# Register Definitions: IP-XACT component
VLNV meklort:<PROJECT>:Register Definitions:1.0

## Address spaces and blocks
DEVICE.DEVICE: base 0xC0000000, range , width , register

## Registers
Registers are 32-bit, access not given, no defined reset value unless marked. A register's access mark holds for its fields unless they carry their own. Offsets are from the block's base; lines under a group give offsets from that group; [hi:lo] are bit positions; {n}, {i} and the like mark numbered series; 'fields as' and 'values as' point back to an identical list; <NAME> marks a mode.

## DEVICE.DEVICE — Device Registers
Base 0xC0000000
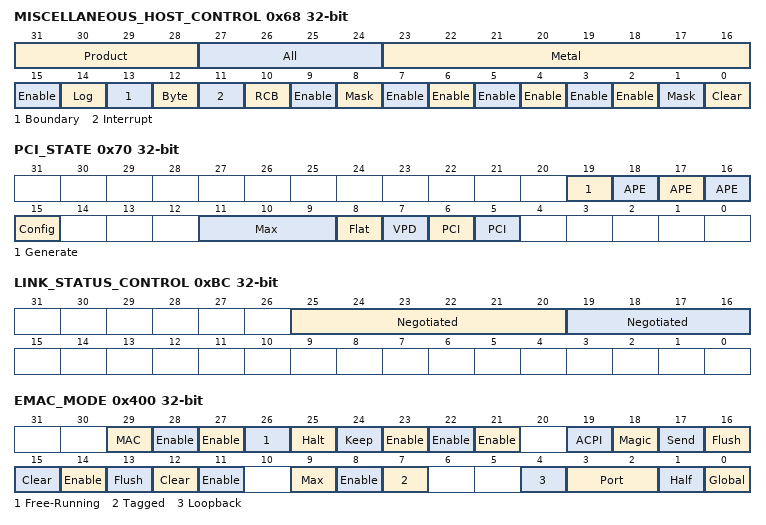
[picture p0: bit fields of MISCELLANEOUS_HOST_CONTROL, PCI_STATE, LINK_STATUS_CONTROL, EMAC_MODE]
0x68 MISCELLANEOUS_HOST_CONTROL rw
  [31:28] Product ID
    15=New Product Mapping
  [27:24] All Layer ID — External All Layer Revision ID.
    0=A; 1=B; 2=C
  [23:16] Metal Rev ID — Metal Rev Number
  [15] Enable TLP Minor Error Tolerance — Set this bit to enable TLP minor error tolerance (ATTR/TC/LOCK command).
  [14] Log Header Overflow — Set this bit to enable log header due to overflow.
  [13] Boundary Check — Set this bit to enable crossing 4 KB boundary check.
  [12] Byte Enable Rule Check — Set this bit to enable the byte enable rule check.
  [11] Interrupt Check — Set this bit to enable the interrupt check.
  [10] RCB Check — Set this bit to enable RCB check.
  [9] Enable Tagged Status Mode — When set, an unique 8-bit tag value will be inserted into the Status block status tag.
  [8] Mask Interrupt Mode — When set, the interrupt is masked.
  [7] Enable Indirect Access — Set this bit to enable indirect addressing mode.
  [6] Enable Register Word Swap — Set this bit to enable word swapping when accessing registers through the PCI target device.
  [5] Enable Clock Control Register Read/Write Capability — Set this bit enable clock control register read/ write capability, otherwise, the clock control register is read only.
  [4] Enable PCI State Register Read/Write Capability — Set this bit to enable PCI state register read/ write capability, otherwise the register is read only.
  [3] Enable Endian Word Swap — Set this bit to enable endian word swapping when accessing through PCIE target interface.
  [2] Enable Endian Byte Swap — Set this bit to enable endian byte swapping when accessing through PCIE target interface.
  [1] Mask Interrupt — Setting this bit will mask future interrupt events from being generated.
  [0] Clear Interrupt — Setting this bit will clear interrupt as long as the mask interrupt bit is not set.
0x70 PCI_STATE rw
  [19] Generate Reset Plus
  [18] APE Program Space Write Enable — When this bit is set the APE program space may be written.
  [17] APE Shared Memory Write Enable — When this bit is set the APE shared memory region may be written.
  [16] APE Control Register Write Enable — When this bit is set the APE control registers may be written.
  [15] Config Retry — When asserted, forces all config access to be retried.
  [11:9] Max PCI Target Retry — Indicates the number of PCI clock cycles before Retry occurs, in multiple of 8.
  [8] Flat View — Asserted if the Base Address register presents a 32 MB PCI Address map flat view, otherwise, indicates a 64 KB PCI Address map in standard view
  [7] VPD Available — This bit reads as 1 if the VPD region of the NVRAM can be accessed by the host
  [6] PCI Expansion ROM Retry — Force PCI Retry for accesses to Expansion ROM region if enabled
  [5] PCI Expansion ROM Desired — Enable PCI ROM base address register to be visible to the PCI host
0x78 REGISTER_BASE — Local controller memory address of a register than can be written or read by writing to the register data register.
0x7C MEMORY_BASE — Local controller memory address of the NIC memory region that can be accessed via Memory Window data register.
0x80 REGISTER_DATA — Register Data at the location pointed by the Register Base Register.
0x88 UNDI_RECEIVE_RETURN_RING_CONSUMER_INDEX — UNDI Receive Return Ring Consumer Index Mailbox
0x8C UNDI_RECEIVE_RETURN_RING_CONSUMER_INDEX_LOW — UNDI Receive Return Ring Consumer Index Mailbox
0xBC LINK_STATUS_CONTROL rw — PCIe standard register.
  [25:20] Negotiated Link Width
  [19:16] Negotiated Link Speed
    1=PCIe 1.0; 2=PCIe 2.0
0xF8 APE_MEMORY_BASE — APE Memory address to read/write using the APE Memory Data register..
0xFC APE_MEMORY_DATA — APE Memory value at the location pointed by the Memory Base Register.
0x160 160 — Unknown register.
0x400 EMAC_MODE rw
  [29] MAC Loopback Mode Control
  [28] Enable APE TX Path — This bit must be written a 1 for the EMAC to transmit APE packets.
  [27] Enable APE RX Path — This bit must be written a 1 for APE subsystem to receive packets from the EMAC.
  [26] Free-Running ACPI — When this bit is set, the ACPI state machine will continue running when a match is found. When this bit is clear, the ACPI state machine will halt when a match is found.
  [25] Halt Interesting Packet PME — When this bit is set, the WOL signal will not be asserted on an interesting packet match.
  [24] Keep Frame In WOL
  [23] Enable FHDE — Enable receive Frame Header DMA engine. Must be set for normal operation.
  [22] Enable RDE — Enable RDMA engine. Must be set for normal operation.
  [21] Enable TCE — Enable Transmit DMA engine.
  [19] ACPI Power On Enable — Enable Wake on LAN filters when in powerdown mode.
  [18] Magic Packet Detection Enable — Enable Magic Packet detection.
  [17] Send Config Command — Send config commands when in TBI mode.
  [16] Flush TX Statistics — Write transmit statistics to external memory. This bit is self-clearing.
  [15] Clear TX Statistics — Clear transmit statistics internal RAM. This bit is self-clearing.
  [14] Enable TX Statistics — Enable transmit statistics external updates.
  [13] Flush RX Statistics — Write receive statistics to external memory. This bit is self-clearing.
  [12] Clear RX Statistics — Clear receive statistics internal RAM. This bit is self-clearing.
  [11] Enable RX Statistics — Enable receive statistics external updates.
  [9] Max Defer — Enable Max Deferral checking statistic.
  [8] Enable TX Bursting — Enable transmit bursting in gigabit half-duplex mode.
  [7] Tagged MAC Control — Allow the MAC to receive tagged MAC control packets.
  [4] Loopback Mode — When set, an internal loopback path is enabled from the transmit MAC to the receive MAC. This bit is provided for diagnostic purposes only.
  [3:2] Port Mode
    0=None; 1=10/100; 2=1000; 3=TBI
  [1] Half Duplex — When set, the MII/GMII interface is configured to operate in half-duplex mode and the CSMA/ CD state machines in the MAC are set to half-duplex mode.
  [0] Global Reset — When this bit is set to 1, the MAC state machine is reset. This is a self-clearing bit.
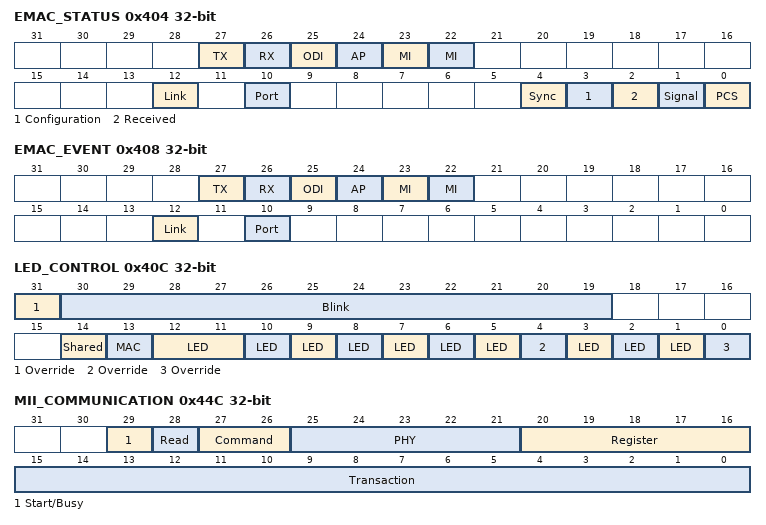
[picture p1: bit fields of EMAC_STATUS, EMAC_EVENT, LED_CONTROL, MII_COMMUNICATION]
0x404 EMAC_STATUS rw
  [27] TX Stat Overrun, [26] RX Stat Overrun, [25] ODI Error, [24] AP Error, [23] MI Interrupt, [22] MI Completion, [12] Link State Changed, [10] Port Detect Error, [4] Sync Changed, [3] Configuration Changed, [2] Received Configuration, [1] Signal Detect, [0] PCS Synced
0x408 EMAC_EVENT rw
  [27] TX Stat Overrun, [26] RX Stat Overrun, [25] ODI Error, [24] AP Error, [23] MI Interrupt, [22] MI Completion, [12] Link State Changed, [10] Port Detect Error
0x40C LED_CONTROL access per field
  [31] Override Blink Rate rw — If set, the blink rate for the Traffic LED is determined by the Blink Period field (bit 30 to bit 19). This bit is rest to 1.
  [30:19] Blink Period rw — Specifies the period of each blink cycle (on+off) for Traffic LED in milliseconds. Must be a nonzero value. This 12-bit field is reset to 0x040, giving a default blink period of approximately 15.9Hz.
  [14] Shared Traffic/Link LED Mode rw — When this bit is set, the Link LED is solid green when there is a link and blinks when there is traffic. (The LED_MODE field must be set to 00 before enabling this bit).
  [13] MAC Mode rw — When this bit is set, the traffic LED blinks only when traffic is addressed for the device (The LED_MODE field must be set to 00 before enabling this bit).
  [12:11] LED Mode rw
    0=MAC (LED signal is in active low (on) when link is established and is in high (off) when link is not established.); 1=PHY Mode 1 (LED signal is in active low (on) when link is established and is in tristate (off) when link is not established.); 2=PHY Mode 2 (LED signal is in active low (on) when link is established and is in high (off) when link is not established.); 3=PHY Mode 3 (Same as PHY mode 1)
  [10] LED Status Traffic readOnly
  [9] LED Status 10 readOnly
  [8] LED Status 100 readOnly
  [7] LED Status 1000 readOnly
  [6] LED Traffic rw — If set along with the Override Traffic bit, the Traffic LED is turned on.
  [5] LED Traffic Blink rw — If set along with the Override Traffic bit and Traffic LED bit, the Traffic LED will blink with the blink rate specified in Override Blink Rate (bit 31) and Blink Period (bits [30:19]) fields.
  [4] Override Traffic rw — If set, overrides hardware control of the Traffic LED. The Traffic LED will then be controlled via bits [6:5].
  [3] LED 10 rw — If set along with the LED Override bit, turns on the 10 Mbps LED.
  [2] LED 100 rw — If set along with the LED Override bit, turns on the 100 Mbps LED.
  [1] LED 1000 rw — If set along with the LED Override bit, turns on the 1000 Mbps LED.
  [0] Override Link rw — If set, overrides hardware control of the three link LEDs. The LEDs will be controlled via bits [3:1].
{0x410+8i} EMAC_MAC_ADDRESSES_{i}_HIGH (i=0..3) — Upper 2-bytes of this node's MAC address.
{0x414+8i} EMAC_MAC_ADDRESSES_{i}_LOW (i=0..3) — Lower 4-byte of this node's MAC address.
0x430 WOL_PATTERN_POINTER — Specifies the offset into the 6KB BD memory for frame comparison. (Bits 3:0 are ignored to align the memory address to a natural 128-bit boundary).
0x434 WOL_PATTERN_CFG
0x438 438 — Unknown register.
0x43C MTU_SIZE rw — 2-byte field which is the largest size frame that will be accepted without being marked as oversize.
  [15:0] MTU
0x44C MII_COMMUNICATION access per field
  [29] Start/Busy rw — Set this bit to start a transaction. While it is high, it indicates that the current transaction is still ongoing. If enabled, generates an attention via EMAC Status Register MI Completion bit (bit 22).
  [28] Read Failed readOnly — When set, the transceiver device did not drive the bus during the attempted read transaction. Valid after the Start/Busy bit is cleared.
  [27:26] Command rw
    1=Write; 2=Read
  [25:21] PHY Address rw
    {v}=PHY {v-1} (v=1..4); {v}=SGMII {v-8} (v=8..11)
  [20:16] Register Address rw — Address of the register to be read or written.
  [15:0] Transaction Data rw — When configured for a write command, the data stored at this location is written to the PHY at the specified PHY and register address. During a read command, the data returned by the PHY is stored at this location.
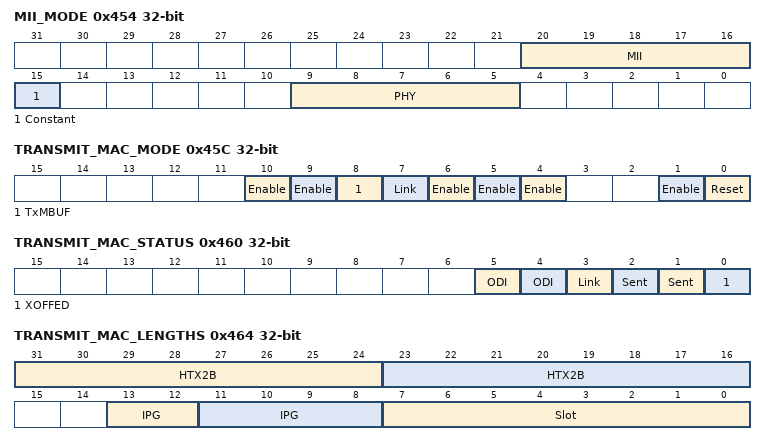
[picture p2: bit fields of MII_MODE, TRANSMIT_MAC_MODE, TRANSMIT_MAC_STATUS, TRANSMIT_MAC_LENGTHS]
0x454 MII_MODE rw
  [20:16] MII Clock Count — Counter to divide CORE_CLK (62.5 MHz) to generate the MI clock. CORE_CLK/2/(MII Clock Count + 1).
  [15] Constant MDIO/MDC Clock Speed — Enable ~500Khz constant MII management interface (MDIO/MDC) frequency regardless core clock frequency.
  [9:5] PHY Address — This field specifies the PHY Address.
0x45C TRANSMIT_MAC_MODE rw
  [10] Enable TX AH Offload — A value 1 enables the TX AH offload feature. When 0, offloaded AH packet gets dropped. This value must be static.
  [9] Enable TX ESP Offload — A value 1 enables the TX ESP offload feature. When 0, offloaded ESP packet gets dropped. This value must be static.
  [8] TxMBUF Corruption Lockup Fix Enable — When set, TXMBUF corruption lockup fix is enabled.
  [7] Link Aware Enable — When set, transmission of packets by the MAC is enabled only when link is up.
  [6] Enable Long Pause — When set, the Pause time value set in the transmitted PAUSE frames is 0xFFFF.
  [5] Enable Big Backoff — MAC will use larger than normal back-off algorithm.
  [4] Enable Flow Control — MAC will send 802.3x flow control frames.
  [1] Enable TDE — Used to be enable TDE in legacy-same purpose.
  [0] Reset — When this bit is set to 1, the Transmit MAC state machine will be reset. This is a self-clearing bit.
0x460 TRANSMIT_MAC_STATUS rw
  [5] ODI Overrun, [4] ODI Underrun, [3] Link Up, [2] Sent XON, [1] Sent XOFF, [0] XOFFED
0x464 TRANSMIT_MAC_LENGTHS rw
  [31:24] HTX2B Count Down Value — HT2XB Count Down Value
  [23:16] HTX2B Jumbo Frame Length — This value + 1500 is used by hardware as the maximum standard frame length for HTX2B. A frame with a length larger than that is a jumbo frame for HTX2B. The length is the effective length of a composed L2 frame as seen from the wire, including the L2 header, L2 payload, and the FCS (CRC) field.
  [13:12] IPG CRS Length — When multiplied by 2, this field indicates the number of bytes from the end of the interpacket gap (IPG) during which incoming carrier is ignored.
  [11:8] IPG Length — When multiplied by 2, this field indicates the number of bytes in the entire IPG.
  [7:0] Slot Time Length — When multiplied by 2, this field indicates the number of bytes in the slot time.
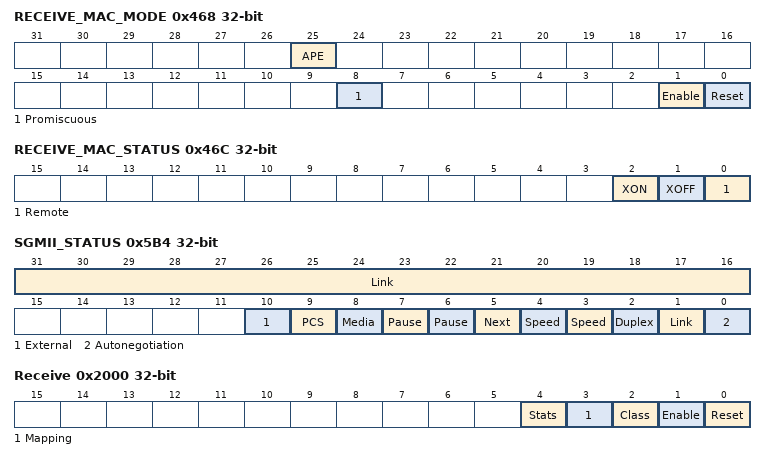
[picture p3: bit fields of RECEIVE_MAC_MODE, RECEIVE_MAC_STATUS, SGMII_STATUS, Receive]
0x468 RECEIVE_MAC_MODE rw
  [25] APE Promiscuous Mode — When set, no source address or MC hashing checking will be performed on incoming frames on APE filter path.
  [8] Promiscuous Mode — When set, no source address or MC hashing checking will be performed on incoming frames.
  [1] Enable — This bit controls whether the Receive MAC state machine is active or not.
  [0] Reset — When this bit is set to 1, the Receive MAC state machine will be reset. This is a self-clearing bit.
0x46C RECEIVE_MAC_STATUS rw
  [2] XON Received, [1] XOFF Received, [0] Remote TX XOFFED
{0x538+8i} PERFECT_MATCH{i}_HIGH rw (i=1..4)
  [15:0] High — Upper two bytes of the MAC
{0x53C+8i} PERFECT_MATCH{i}_LOW rw (i=1..4)
  [31:0] Low — Lower four bytes of the MAC
0x5B4 SGMII_STATUS access per field — This register reflects various status of the respective SGMII port when enabled.
  [31:16] Link Partner Autonegotiation Capability rw
  [10] External CRS Detect rw
  [9] PCS CRS Detect rw
  [8] Media Selection Mode readOnly
    0=Copper; 1=SGMII
  [7] Pause TX readOnly
  [6] Pause RX readOnly
  [5] Next Page RX readOnly
  [4] Speed 100 readOnly — The SGMII Link currently operable at 100mbps data speed.
  [3] Speed 1000 readOnly — The SGMII Link currently operable at 1 Gbps data speed.
  [2] Duplex Status readOnly
  [1] Link Status readOnly
  [0] Autonegotiation Complete readOnly — Auto-negotiation process has completed.
0x2000 Receive List Placement Mode rw
  [4] Stats Overflow Attention Enable — Enable attention for statistics overflow.
  [3] Mapping out of Range Attention Enable — Enable attention for mapping out of range error.
  [2] Class Zero Attention Enable — Enable attention for zero class field.
  [1] Enable — This bit controls whether the Receive List Placement state machine is active or not. When set to 0, it completes the current operation and cleanly halts. Until it is completely halted, it remains one when read.
  [0] Reset — When this bit is set to 1, the Receive List Placement state machine is reset. This is a self clearing bit.
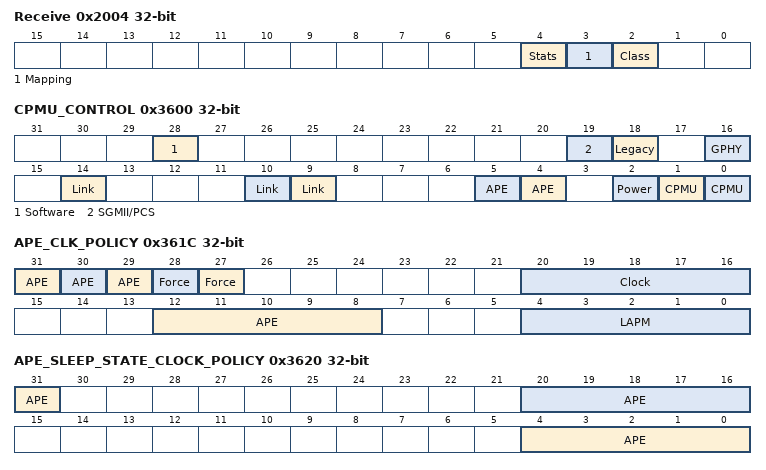
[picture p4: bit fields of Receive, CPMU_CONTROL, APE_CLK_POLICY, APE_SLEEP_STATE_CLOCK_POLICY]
0x2004 Receive List Placement Status rw
  [4] Stats Overflow Attention — A statistics managed by Receive List Placement has overflowed.
  [3] Mapping out of Range Attention — Class of service mapping is out of the range of the active queue number.
  [2] Class Zero Attention — Class field extracted from frame descriptor is zero.
0x3600 CPMU_CONTROL rw
  [28] Software Controlled GPHY Force DLL On, [19] SGMII/PCS Power Down, [18] Legacy Timer Enable, [16] GPHY 10MB Receive Only Mode Enable, [14] Link Speed Power Mode Enable, [10] Link Aware Power Mode Enable, [9] Link Idle Power Mode Enable, [5] APE Deep Sleep Mode Enable, [4] APE Sleep Mode Enable, [2] Power Down, [1] CPMU Register Software Reset, [0] CPMU Software Reset
0x3604 NO_LINK_POWER_MODE_CLOCK_POLICY rw
  [20:16] MAC Clock Switch — Software Controlled MAC Core Clock Speed Select.
    0=62.5MHz; 1=60.0MHz; 3=30.0MHz; 5=15.0MHz; 7=7.5MHz; 9=3.75MHz; 17=12.5MHz (CK25/2); 19=6.25MHz (CK25/4); 21=3.125MHz (CK25/8); 23=1.563MHz (CK25/16); 31=12.5MHz/1.25MHz (MII_CLK/2)
0x3610 LINK_AWARE_POWER_MODE_CLOCK_POLICY rw
  [20:16] MAC Clock Switch — Software Controlled MAC Core Clock Speed Select.
    1=60.0MHz; 3=30.0MHz; 5=15.0MHz; 7=7.5MHz; 9=3.75MHz; 17=12.5MHz; 19=6.25MHz; 21=3.125MHz; 23=1.563MHz; 25=781kHz; 31=12.5MHz/1.25MHz
0x3614 D0U_CLOCK_POLICY rw
  fields as LINK_AWARE_POWER_MODE_CLOCK_POLICY
0x361C APE_CLK_POLICY rw
  [31] APE Sleep mode Enable
  [30] APE Deep Sleep mode Enable
  [29] APE Clock Speed Override Enable
  [28] Force APE FCLK Disable
  [27] Force APE HCLK Disable
  [20:16] Clock Override APE Clock Switch — Software Controlled APE Clock Speed Select for Clock Override.
    30=125 MHz; 0=62.5 MHz; 9=25 MHz; 19=12.5 MHz; 21=6.25 MHz; 23=3.125 MHz; 25=1.563 MHz
  [12:8] APE Clock Switch — Software Controlled APE Clock Speed Select
    values as Clock
  [4:0] LAPM APE Clock Switch — Software Controlled APE Clock Speed Select in Link Aware Power mode
    17=25 MHz; 19=12.5 MHz; 21=6.25 MHz; 23=3.125 MHz; 25=1.563 MHz
0x3620 APE_SLEEP_STATE_CLOCK_POLICY rw
  [31] APE Sleep HCLK Disable — Software Controlled APE HCLK shutoff in sleep and deep sleep state
  [20:16] APE Deep Sleep FCLK Switch — Software Controlled APE Clock Speed Select
  [4:0] APE Sleep FCLK Switch — Software Controlled APE Clock Speed Select
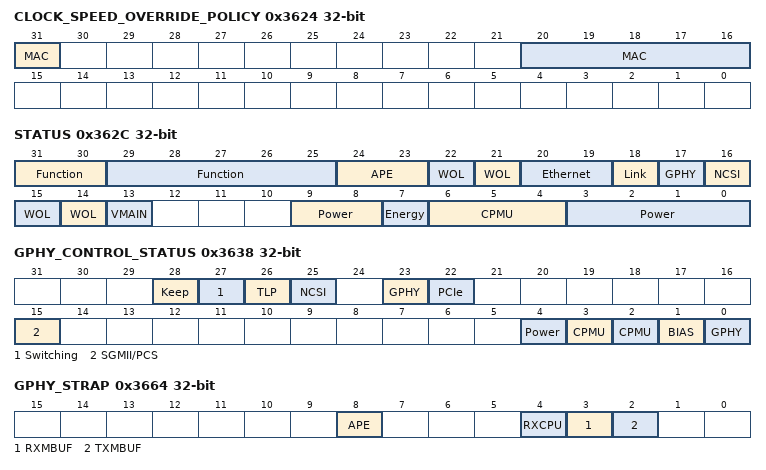
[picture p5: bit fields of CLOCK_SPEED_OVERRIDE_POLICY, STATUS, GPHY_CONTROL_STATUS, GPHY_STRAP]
0x3624 CLOCK_SPEED_OVERRIDE_POLICY rw
  [31] MAC Clock Speed Override Enabled — Enable MAC clock speed override
  [20:16] MAC Clock Switch — Software Controlled MAC Core Clock Speed Select
0x362C STATUS readOnly
  [31:30] Function Number — PCIE function number
  [29:25] Function Enable — Function Enable input from System BIOS
  [24:23] APE Status — APE Engine Status
    0=Active; 1=Sleep; 2=Deep Sleep
  [22] WOL ACPI Detection Enable Port 1
  [21] WOL Magic Packet Detection Enable Port 1
  [20:19] Ethernet Link Status
    0=1000 Mb; 1=100 Mb; 2=10 Mb; 3=No Link
  [18] Link Idle Status
  [17] GPHY DLL Lock Status
  [16] NCSI DLL Lock Status
  [15] WOL ACPI Detection Enable Port 0
  [14] WOL Magic Packet Detection Enable Port 0
  [13] VMAIN Power Status
  [9:8] Power State
  [7] Energy Detect Status
  [6:4] CPMU Power State
  [3:0] Power Management State Machine State
0x3630 CLOCK_STATUS
0x3638 GPHY_CONTROL_STATUS rw
  [28] Keep NCSI PLL on during low power mode.
  [27] Switching Regulator Power Down
  [26] TLP Clock Source
  [25] NCSI PLL Lock Status
  [23] GPHY PLL Lock Status
  [22] PCIe PLL Lock Status
  [15] SGMII/PCS Power Down — Setting this bit will powerdown SGMII-PCS module.
  [4] Power Down — Force CPMU into Low Power State, LAN function will be powered down (GPHY, PCIE, IPSEC, APE). This bit is cleared by a rising edge of PERST_L.
  [3] CPMU Register Software Reset — Software reset for resetting all the registers to default.
  [2] CPMU Software Reset — Software reset for all the CPMU logic expect for registers.
  [1] BIAS IDDQ — When this bit is set, BIAS will be powered down.
  [0] GPHY IDDQ — When this bit is set, GPHY will be powered down.
0x3658 CHIP_ID
0x365C MUTEX_REQUEST rw — Writing a 1 to any of these bits pends a Mutex lock request on behalf of a software agent. The bit is subsequently latched by hardware and shall read 1 as long as the request is pending. Writing a 0 to a bit shall have no effect.
  [15:0] Request
0x3660 MUTEX_GRANT rw — Reading this field shall return a maximum of one set bit at any time. The set bit shall point to the lock owner. If the Mutex is not locked, then a read shall return a value 0x0000. Writing a 1 to the already set bit shall relinquish the lock and the set bit shall be cleared. Writing a 1 to an unset bit shall cancel the corresponding pending request if there was one, and the pairing bit in the Mutex_Request_Reg shall be cleared.
  [15:0] Granted
0x3664 GPHY_STRAP rw
  [8] APE CM3 Big Endian Enable — Enable APE CM3 Big Endian Setting
  [4] RXCPU SPAD ECC Enable — Enable ECC for rxcpu scratchpad.
  [3] RXMBUF ECC Enable — Enable RXMBUF ECC.
  [2] TXMBUF ECC Enable — Enable TXMBUF ECC.
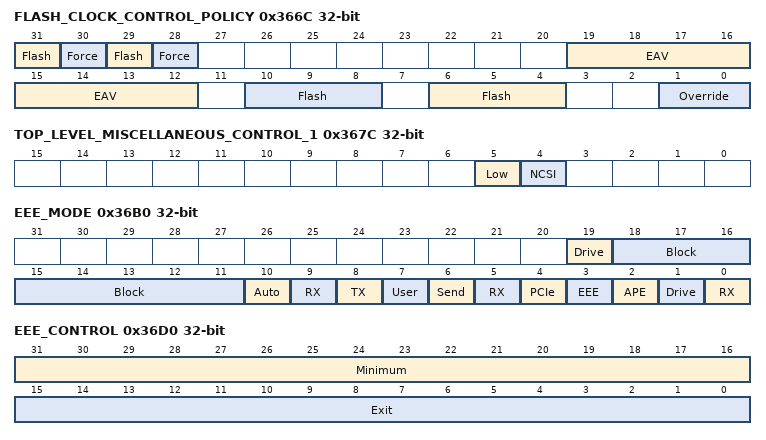
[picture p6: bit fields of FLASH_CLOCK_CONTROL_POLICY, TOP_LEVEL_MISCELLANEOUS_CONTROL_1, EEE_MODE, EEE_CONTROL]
0x366C FLASH_CLOCK_CONTROL_POLICY rw
  [31] Flash Clock Speed Override
  [30] Force Flash Clock Disable
  [29] Flash Idle mode Enable
  [28] Force EAV Clock Disable
  [19:12] EAV Clock Policy — Software Controlled EAV Clock Speed Select
    0=4.8MHz; 1=1250 MHz; 10=125 MHz
  [10:8] Flash Idle Clock Policy — Software Controlled Flash Clock Speed
    0=62.5 MHz NCSI DLL; 3=25 MHz
  [6:4] Flash Clock Policy — Software Controlled Flash Clock Speed
    0=62.5 MHz NCSI DLL; 3=25 MHz
  [1:0] Override Flash Clock Switch — Software Controlled Flash Clock Speed
    0=62.5 MHz NCSI DLL; 3=25 MHz
0x367C TOP_LEVEL_MISCELLANEOUS_CONTROL_1 rw
  [5] Low Power IDDQ Mode, [4] NCSI Clock Output Disable
0x36B0 EEE_MODE rw
  [19] Drive Allow LPI Enable, [18:11] Block Time, [10] Auto Wake Enable, [9] RX LPI Enable, [8] TX LPI Enable, [7] User LPI Enable, [6] Send Index Detection Enable, [5] RX CPU Allow LPI Enable, [4] PCIe L1 Exit Detection Enable, [3] EEE Link Idle Detection Enable, [2] APE TX Detection Enable, [1] Drive Allow LPI, [0] RX CPU Allow LPI
0x36BC EEE_LINK_IDLE_CONTROL rw
  [2] Debug UART Idle
0x36D0 EEE_CONTROL rw
  [31:16] Minimum Assert
  [15:0] Exit Time
    0x19D=16.5 us; 0x1F8=20.1 us; 0x384=36 us
0x36F0 GLOBAL_MUTEX_REQUEST rw
  [15:0] Request — Writing a 1 to any of these bits pends a Mutex lock request on behalf of a software agent. The bit is subsequently latched by hardware and shall read 1 as long as the request is pending. Writing a 0 to a bit shall have no effect.
0x36F4 GLOBAL_MUTEX_GRANT rw
  [15:0] Granted — Reading this field shall return a maximum of one set bit at any time. The set bit shall point to the lock owner. If the Mutex is not locked, then a read shall return a value 0x0000. Writing a 1 to the already set bit shall relinquish the lock and the set bit shall be cleared. Writing a 1 to an unset bit shall cancel the corresponding pending request if there was one, and the pairing bit in the Mutex_Request_Reg shall be cleared.
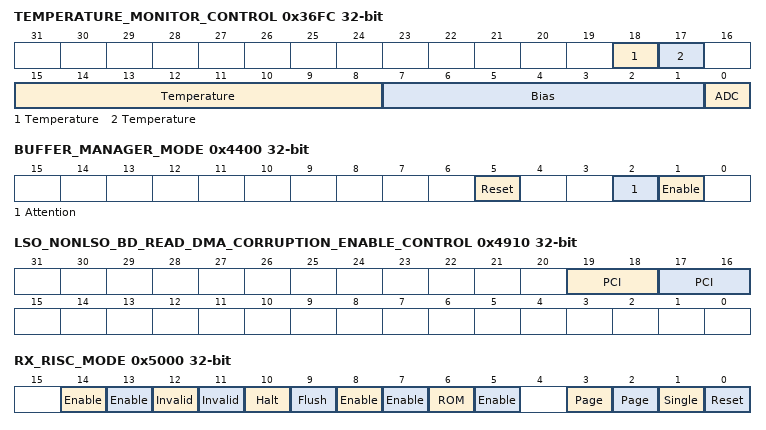
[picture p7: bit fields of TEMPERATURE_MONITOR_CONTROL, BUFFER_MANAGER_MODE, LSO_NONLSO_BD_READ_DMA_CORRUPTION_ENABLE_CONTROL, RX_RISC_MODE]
0x36FC TEMPERATURE_MONITOR_CONTROL rw
  [18] Temperature Monitor Power Down, [17] Temperature Monitor Hold, [15:8] Temperature Data, [7:1] Bias Adjust, [0] ADC Test Enable
0x4000 MEMORY_ARBITER_MODE rw
  [1] Enable
0x4400 BUFFER_MANAGER_MODE rw
  [5] Reset RXMBUF Pointer — When this bit is set, it will cause the RXMBUF allocation and deallocation pointer to reset back to the RXMBUF base.
  [2] Attention Enable — When this bit is set to 1, an internal attention is generated when an error occurs.
  [1] Enable — This bit controls whether the Buffer Manager is active or not.
0x4910 LSO_NONLSO_BD_READ_DMA_CORRUPTION_ENABLE_CONTROL rw
  [19:18] PCI Request Burst Length for NonLSO RDMA Engine
    0=128B; 1=256B; 2=512B; 3=4K
  [17:16] PCI Request Burst Length for BD RDMA Engine
    0=128B; 1=256B; 2=512B; 3=4K
0x5000 RX_RISC_MODE access per field
  [14] Enable Register Address Trap Halt rw — When set, if the GRC raises the trap signal to this processor, it will halt. CLeared on reset and Watchdog interrupt.
  [13] Enable Memory Address Trap Halt rw — When set, if the MA raises the trap signal to this processor, it will halt. CLeared on reset and Watchdog interrupt.
  [12] Invalid Instruction Access Halt rw — When set, the condition that causes RX RISC state bit 6 to be set, also halts the RX RISC. Set by reset.
  [11] Invalid Data Access Halt rw — When set, the condition that causes RX RISC state bit 5 to be set, also halts the RX RISC. Set by reset.
  [10] Halt rw — Set by TX RISC or the host to halt the RX RISC. Cleared on reset and Watchdog interrupt.
  [9] Flush Instruction Cache rw — Self-clearing bit which forces the instruction cache to flush.
  [8] Enable Instruction Cache rw — Enables prefetch logic within the instruction cache. When disabled only a single cache line is read on a cache miss. Cleared on reset.
  [7] Enable Watchdog rw — Enables watchdog interrupt state machine. Used in conjunction with Watchdog Clear register, Watchdog Saved PC register and Watchdog Vector register. Cleared on reset and Watchdog interrupt.
  [6] ROM Fail rw — Asserted on reset. Cleared by ROM code after it successfully loads code from NVRAM. Afterwards, this bit can be used by software for any purpose.
  [5] Enable Data Cache rw — Enables the data cache. Cleared on reset. Note: Firmware developers should take care to clear this bit before polling internal SRAM memory locations, because the RX RISC processor uses a two-element LRU caching algorithm, which is not affected by writes from the PCI interface.
  [3] Page 0 Instr Halt writeOnly — When set, instruction references to the first 256 bytes of SRAM force the RX RISC to halt and cause bit 4 in the RX RISC state register to be latched. Cleared on reset and Watchdog interrupt.
  [2] Page 0 Data Halt writeOnly — When set, data references to the first 256 bytes of SRAM force the RX RISC to halt and cause bit 3 in the RX RISC state register to be latched. Cleared on reset and Watchdog interrupt.
  [1] Single Step rw — Advances the RX RISC's PC for one cycle. If halting condition still exists, the RX RISC will again halt; otherwise, it will resume normal operation.
  [0] Reset writeOnly — Self-clearing bit which resets only the RX RISC.
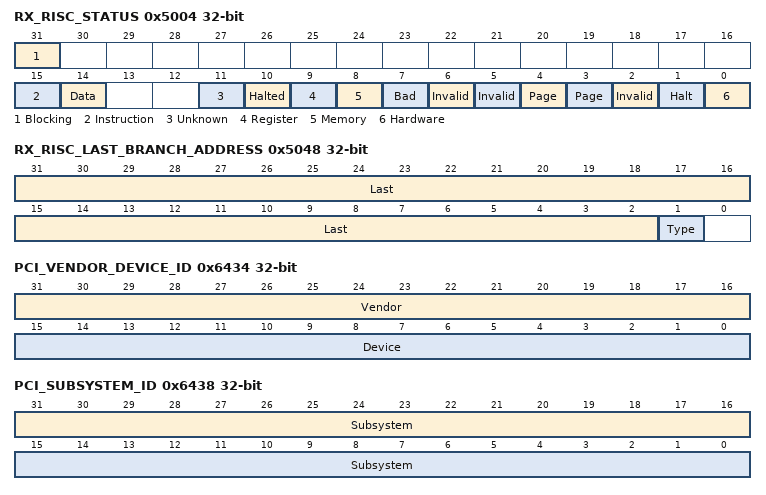
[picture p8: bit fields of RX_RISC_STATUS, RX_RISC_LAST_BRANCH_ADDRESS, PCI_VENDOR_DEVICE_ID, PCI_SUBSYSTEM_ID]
0x5004 RX_RISC_STATUS rw
  [31] Blocking Read — A blocking data cache miss occurred, causing the RX RISC to stall while data is fetched from external (to the RX RISC) memory. This is intended as a debugging tool. No state is saved other than the fact that the miss occurred.
  [15] Instruction Fetch Stall — The processor is currently stalled due to an instruction fetch.
  [14] Data Access Stall — The processor is currently stalled due to a data access.
  [11] Unknown
  [10] Halted — The RX RISC was explicitly halted via bit 10 in the RX RISC Mode register.
  [9] Register Address Trap — A signal was received from the Global Resources block indicating that this processor accessed a register location that triggered a software trap. The GRC registers are used to configure register address trapping.
  [8] Memory Address Trap — A signal was received from the Memory Arbiter indicating that some BCM5700 block, possibly this processor, accessed a memory location that triggered a software trap. The MA registers are used to configure memory address trapping.
  [7] Bad Memory Alignment — Load or Store instruction was executed with the least significant two address bits not valid for the width of the operation (e.g., Load word or Load Half-word from an odd byte address).
  [6] Invalid Instruction Fetch — Program Counter (PC) is set to invalid location in processor address space.
  [5] Invalid Data Access — Data reference to illegal location.
  [4] Page 0 Instruction Reference — When enabled in mode register, indicates the address in the PC is within the lower 256 bytes of SRAM.
  [3] Page 0 Data Refeence — When enabled in mode register, indicates data reference within lower 256 bytes of SRAM.
  [2] Invalid Instruction — Invalid instruction fetched.
  [1] Halt Instruction Executed — When enabled in mode register, indicates hardware breakpoint has been reached.
  [0] Hardware Breakpoint — When enabled in mode register, indicates hardware breakpoint has been reached.
0x5008 RX_RISC_EVENT_MASK
0x501C RX_RISC_PROGRAM_COUNTER — The program counter register can be used to read or write the current Program Counter of the each CPU. Reads can occur at any time, however writes can only be performed when the CPU is halted. Writes will also clear any pending instruction in the decode stage of the pipeline. Bits 31-2 are implemented. 1s written to bits 1-0 are ignored.
0x5020 RX_RISC_CURRENT_INSTRUCTION — This register allows access instruction in the decode sate of the pipeline while the processor is halted. This register is only intended for debugging use. This register may be used to replace a halt instruction with some other instruction after the halt has been executed.
0x5028 RX_RISC_INTERRUPT_ENABLE — Any write to this register will enable CPU Interrupts (set bit 7 in mode register). This register is intended to allow a way to return from an interrupt service routine (ISR) using only 2 general purpose registers. MIPS conventions reserve registers 26 and 27 (k0 and k1) for use by an interrupt handler. At the end of an ISR, k0 should be loaded with the return address from the CPU Interrupt Saved PC register. Then k1 should be loaded with the address of the CPU Interrupt Enable register. The last 2 instructions in the ISR should be a jump register (jr) to k0 followed immediately by a store word (sw) to k1. This ensures that we can’t respond to another interrupt until we are safely out of the ISR. Interrupts can also be enabled through the CPU Mode Register. They can be disabled only through the CPU Mode Register. Each time this register is written, bit 7 of the mode register is set. The data value of the write is not used. The read value of this register is always zero.
0x502C RX_RISC_INTERRUPT_VECTOR — This register sets the program counter value that will be loaded when an interrupt is performed due to the interrupt input.
0x5034 RX_RISC_HARDWARE_BREAKPOINT — This register is used to set a hardware breakpoint based on the RISC's program counter (PC). If the PC equals the value in this register, and the hardware breakpoint is enabled, the RISC is halted and the appropriate stopping condition is indicated in the RISC State Register. To enable the hardware breakpoint, simply write the byte address of the instruction to break on and clear the Disable Hardware Breakpoint bit.
0x5048 RX_RISC_LAST_BRANCH_ADDRESS rw — This register indicates that address and branch type of the last branch that was taken. This register is for debug use only.
  [31:2] Last Branch Address — This value indicates the address of the last branch that was taken. An offset as indicated by the type field must be subtracted from this value.
  [1] Type — This indicates the jump or branch type.
    0=Jump (4 bytes must be subtracted from the LBA value to determine the actual address of the branch instruction that caused this register to load.); 1=Branch (8 bytes must be subtracted from the LBA value to determine the actual address of the branch instruction that caused this register to load.)
0x5200 RX_RISC_REGISTER_0 — $zero (R0)
0x5204 RX_RISC_REGISTER_1 — $at (R1)
0x5208 RX_RISC_REGISTER_2 — $v0 (R2)
0x520C RX_RISC_REGISTER_3 — $v1 (R3)
{0x5200+4i} RX_RISC_REGISTER_{i} (i=4..7) — $a{i-4} (R{i})
{0x5200+4i} RX_RISC_REGISTER_{i} (i=8..15) — $t{i-8} (R{i})
{0x5200+4i} RX_RISC_REGISTER_{i} (i=16..23) — $s{i-16} (R{i})
0x5260 RX_RISC_REGISTER_24 — $t8 (R24)
0x5264 RX_RISC_REGISTER_25 — $t9 (R25)
0x5268 RX_RISC_REGISTER_26 — $k0 (R26)
0x526C RX_RISC_REGISTER_27 — $k1 (R27)
0x5270 RX_RISC_REGISTER_28 — $gp (R28)
0x5274 RX_RISC_REGISTER_29 — $sp (R29)
0x5278 RX_RISC_REGISTER_30 — $fp (R30)
0x527C RX_RISC_REGISTER_31 — $ra (R31)
0x6408 6408
0x6410 PCI_POWER_CONSUMPTION_INFO — This undocumented register is used to set PCIe Power Consumption information as reported in configuration space. It is loaded from NVM configuration data.
0x6414 PCI_POWER_DISSIPATED_INFO — This undocumented register is used to set PCIe Power Dissipated information as reported in configuration space. It is loaded from NVM configuration data.
0x642C PCI_VPD_REQUEST rw — This undocumented register appears to be used to implement the PCI VPD capability. It is set to the VPD offset which was requested by the host by writing to the VPD register.
  [30:16] Requested VPD Offset
0x6430 PCI_VPD_RESPONSE — This undocumented register appears to be used to implement the PCI VPD capability. Bootcode writes the 32 bits of data loaded from the word requested by
0x6434 PCI_VENDOR_DEVICE_ID rw — This is the undocumented register used to set the PCI Vendor/Device ID, which is configurable from NVM.
  [31:16] Vendor ID, [15:0] Device ID
0x6438 PCI_SUBSYSTEM_ID rw — This is the undocumented register used to set the PCI Subsystem/Subsystem Vendor ID, which is configurable from NVM.
  [31:16] Subsystem ID, [15:0] Subsystem Vendor ID
0x643C PCI_CLASS_CODE_REVISION — This undocumented register is suspected to set the class code and device revision in PCI configuration space. Unconfirmed.
0x64C0 64C0
0x64C4 64C4
0x64C8 64C8
0x64DC 64DC
0x6504 PCI_SERIAL_NUMBER_LOW — This sets the low 32 bits of the 64-bit device serial number, which isexposed as a PCIe capability in configuration space.
0x6508 PCI_SERIAL_NUMBER_HIGH — This sets the high 32 bits of the 64-bit device serial number, which isexposed as a PCIe capability in configuration space.
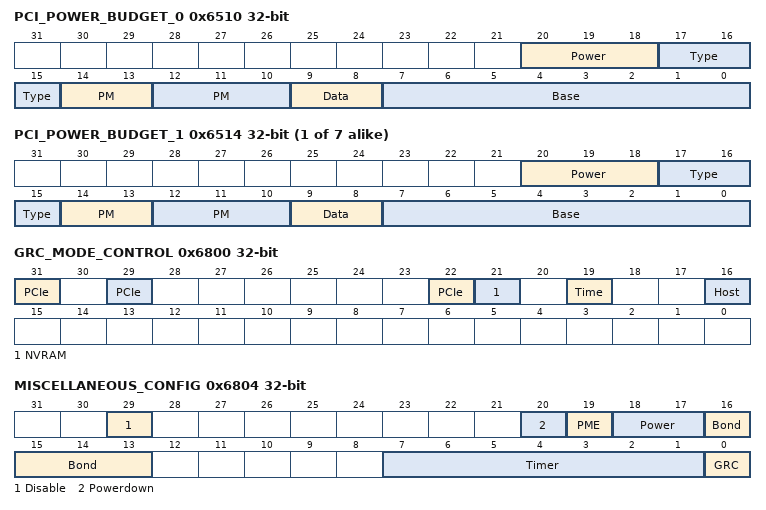
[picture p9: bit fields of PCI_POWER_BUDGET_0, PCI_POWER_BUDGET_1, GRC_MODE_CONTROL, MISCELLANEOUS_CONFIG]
0x6510 PCI_POWER_BUDGET_0 rw — Used to report power budget capability data to the host. The values are loaded from NVM, and up to eight values may be specified.
  [20:18] Power Rail — Specifies the thermal load or power rail of the operating condition being described.
    0=Power 12V; 1=Power 3.3V; 2=Power 1.5V or 1.8V; 7=Thermal
  [17:15] Type — Specifies the power management state of the operating condition being described.
    0=PME Aux; 1=Auxiliary; 2=Idle; 3=Sustained; 7=Maximum
  [14:13] PM State — Specifies the power management state of the operating condition being described.
    {v}=D{v} (v=0..3)
  [12:10] PM Sub State — Specifies the power management sub state of the operating condition being described.
  [9:8] Data Scale — Specifies the scale to apply to the Base Power value.
    0=1.0x; 1=0.1x; 2=0.01x; 3=0.001x
  [7:0] Base Power — Specifies in watts the base power value in the given operating condition.
{0x6510+4i} PCI_POWER_BUDGET_{i} rw (i=1..7) — See
  fields as PCI_POWER_BUDGET_0
0x6530 6530
0x6550 6550 — The LSB in this undocumented and unknown register is set if the device is a LOM (LAN-on-Motherboard) design (i.e., builtin to a system and not an expansion card).
0x65F4 65F4
0x6800 GRC_MODE_CONTROL rw
  [31] PCIe TL/DL/PL Mapping 3
  [29] PCIe TL/DL/PL Mapping 2
  [22] PCIe TL/DL/PL Mapping 1
  [21] NVRAM Write Enable — The host must set this bit before attempting to update the Flash or SEEPROM.
  [19] Time Sync Mode Enable — Write 1 to this bit to enable Time Sync Mode.
  [16] Host Stack Up — The host stack is ready to receive data from the NIC.
0x6804 MISCELLANEOUS_CONFIG rw
  [29] Disable GRC Reset — Setting this bit will prevent reset to PCIE block.
  [20] Powerdown — Setting this bit will power down the device (power consumption is ~20 mW). This bit is cleared by PCI reset.
  [19] PME EN State — State of PME Enable for this device.
  [18:17] Power State — Indicates the current power state of the device.
    {v}=D{v} (v=0..3)
  [16:13] Bond ID
  [7:1] Timer Prescaler — Local Core clock frequency in MHz, minus 1, which should correspond to each advance of the timer. Reset to all 1.
  [0] GRC Reset — Write 1 to this bit resets the CORE_CLK blocks in the device. This is a self-clearing bit.
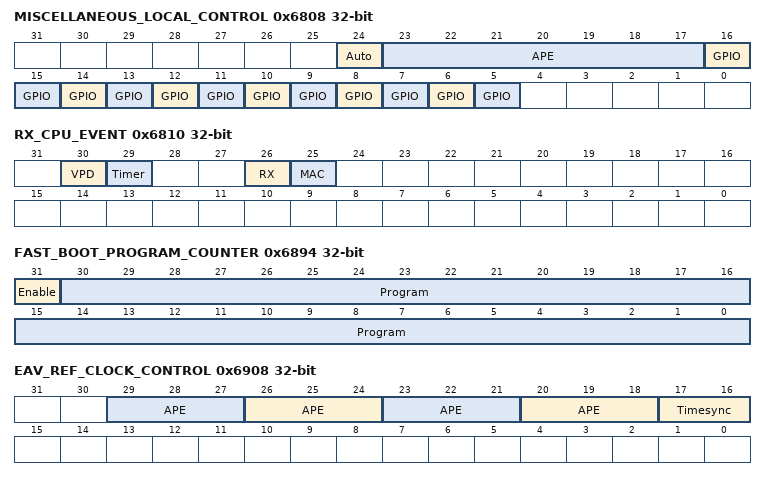
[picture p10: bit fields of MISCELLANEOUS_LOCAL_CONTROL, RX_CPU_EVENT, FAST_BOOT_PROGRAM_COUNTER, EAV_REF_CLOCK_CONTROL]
0x6808 MISCELLANEOUS_LOCAL_CONTROL rw
  [24] Auto SEEPROM Access, [23:17] APE GPIO In, [16] GPIO 2 Output, [15] GPIO 1 Output, [14] GPIO 0 Output, [13] GPIO 2 Output Enable, [12] GPIO 1 Output Enable, [11] GPIO 0 Output Enable, [10] GPIO 2 Input, [9] GPIO 1 Input, [8] GPIO 0 Input, [7] GPIO 3 Output, [6] GPIO 3 Output Enable, [5] GPIO 3 Input
0x680C TIMER — 32-bit free-running counter
0x6810 RX_CPU_EVENT rw
  [30] VPD Attention, [29] Timer, [26] RX CPU Attention, [25] MAC Attention
0x6838 6838 — Unknown. Used by PXE agent.
0x6844 MDI_CONTROL — The register manual only mentions this in the changelog; it was removed from the manual in a previous revision. :|
0x684C RX_CPU_EVENT_ENABLE rw
  [30] VPD Attention
0x6894 FAST_BOOT_PROGRAM_COUNTER rw
  [31] Enable — This bit is used by the CPU to keep track of whether or not there is valid phase 1 boot code stored in the RX MBUF. If the bit is set, then RXMBUF contains valid boot code. Otherwise, it is assumed that RXMBUF does not contain valid boot code.
  [30:0] Program Counter — This field is used by the CPU to keep track of the location of the phase 1 boot code in RX MBUF.
0x68EC EXPANSION_ROM_ADDR — Expansion ROM base address, expect to be d- word aligned.
0x68F0 68F0
0x6908 EAV_REF_CLOCK_CONTROL rw
  [3n+20:3n+18] APE GPIO {n} Mapping (n=0..3) — APE_GPIO[{n}] pin is mapped to 1588 input/ output via this field
    0=Not Used; 4=Snap-Shot[0]; 5=Snap-Shot[1]; 6=Time Watchdog[0]; 7=Time Watchdog[1]
  [17:16] Timesync GPIO Mapping — The MAC/Port dedicated TimeSync_GPIO pin is mapped via this field
    0=Snap-Shot[0]; 1=Snap-Shot[1]; 2=Time Watchdog[0]; 3=Time Watchdog[1]
0x7C04 7C04 — PCIe Transaction Cfg
